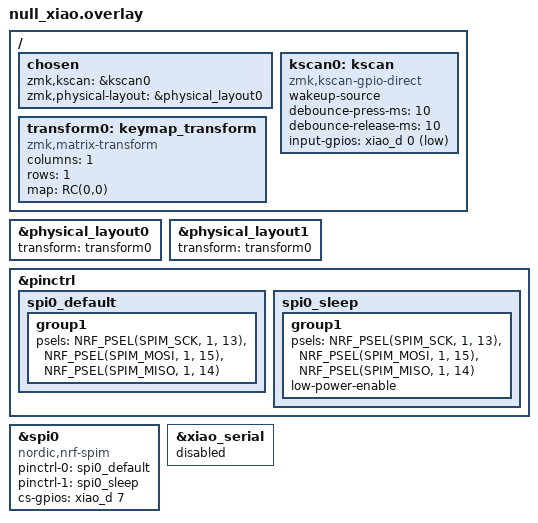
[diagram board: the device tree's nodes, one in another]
#include <dt-bindings/zmk/matrix_transform.h>
#include "null_xiao-layouts.dtsi"

&physical_layout0 {
    transform = <&transform0>;
};

&physical_layout1 {
    transform = <&transform0>;
};

/ {
    chosen {
        zmk,kscan = &kscan0;
        zmk,physical-layout = &physical_layout0;
    };

    kscan0: kscan {
        compatible = "zmk,kscan-gpio-direct";
        wakeup-source;
        debounce-press-ms = <10>;
        debounce-release-ms = <10>;
        input-gpios = <&xiao_d 0 (GPIO_ACTIVE_LOW | GPIO_PULL_UP)>;
    };

    transform0: keymap_transform {
        compatible = "zmk,matrix-transform";
        columns = <1>;
        rows = <1>;
        map = <RC(0,0)>;
    };
};


//REQUIRED FOR DISPLAY
&pinctrl {
    spi0_default: spi0_default {
        group1 {
            psels = <NRF_PSEL(SPIM_SCK, 1, 13)>,
                <NRF_PSEL(SPIM_MOSI, 1, 15)>,
                <NRF_PSEL(SPIM_MISO, 1, 14)>;
        };
    };
    spi0_sleep: spi0_sleep {
        group1 {
            psels = <NRF_PSEL(SPIM_SCK, 1, 13)>,
                <NRF_PSEL(SPIM_MOSI, 1, 15)>,
                <NRF_PSEL(SPIM_MISO, 1, 14)>;
            low-power-enable;
        };
    };
};

nice_view_spi: &spi0 {
    compatible = "nordic,nrf-spim";
    pinctrl-0 = <&spi0_default>;
    pinctrl-1 = <&spi0_sleep>;
    pinctrl-names = "default", "sleep";
    cs-gpios = <&xiao_d 7 GPIO_ACTIVE_HIGH>;
};

&xiao_serial { status = "disabled"; };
